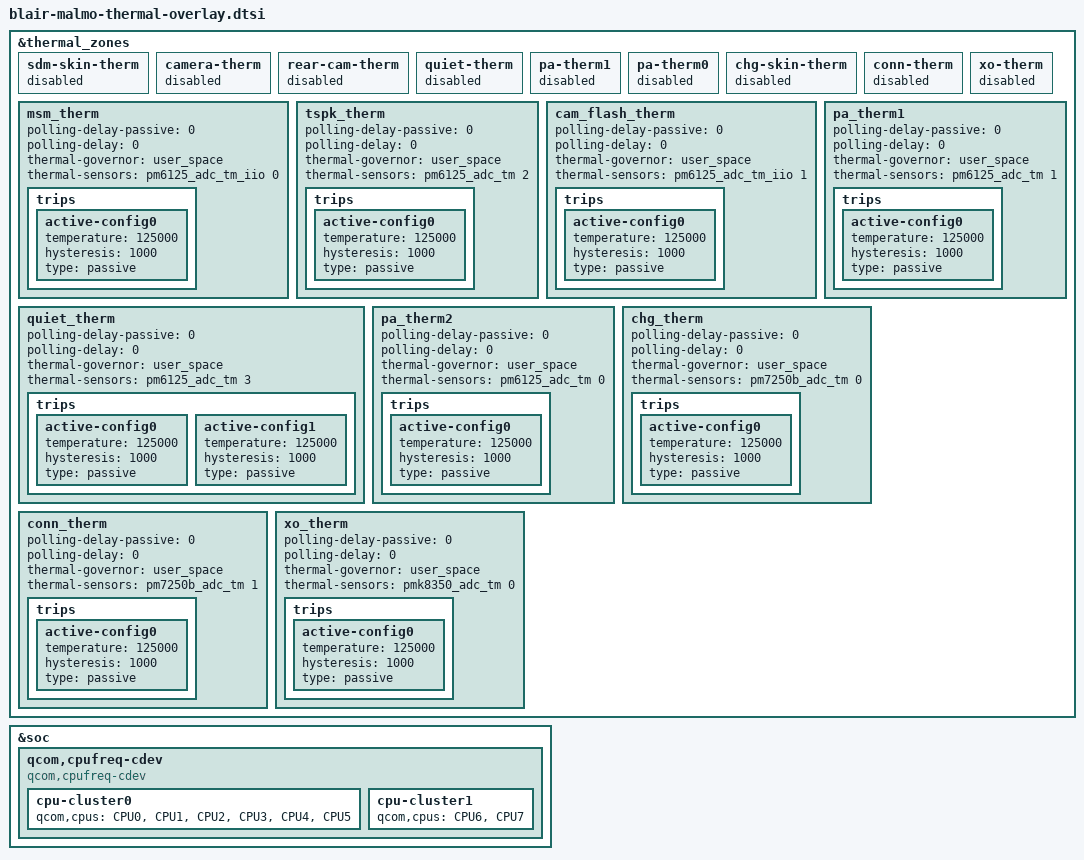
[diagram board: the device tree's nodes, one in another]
#include "moto_therm_sys_temp.dtsi"

/*
&socd_trip {
	temperature = <98>;
};
*/

&thermal_zones {
	sdm-skin-therm {
		status = "disabled";
	};

	camera-therm {
		status = "disabled";
	};

	rear-cam-therm {
		status = "disabled";
	};

	quiet-therm {
		status = "disabled";
	};

	pa-therm1 {
		status = "disabled";
	};

	pa-therm0 {
		status = "disabled";
	};

	chg-skin-therm {
		status = "disabled";
	};

	conn-therm {
		status = "disabled";
	};

	xo-therm {
		status = "disabled";
	};

	msm_therm {
		polling-delay-passive = <0>;
		polling-delay = <0>;
		thermal-governor = "user_space";
		thermal-sensors = <&pm6125_adc_tm_iio 0>;
		trips {
			active-config0 {
				temperature = <125000>;
				hysteresis = <1000>;
				type = "passive";
			};
		};
	};

	tspk_therm {
		polling-delay-passive = <0>;
		polling-delay = <0>;
		thermal-governor = "user_space";
		thermal-sensors = <&pm6125_adc_tm 2>;
		trips {
			active-config0 {
				temperature = <125000>;
				hysteresis = <1000>;
				type = "passive";
			};
		};
	};

	cam_flash_therm {
		polling-delay-passive = <0>;
		polling-delay = <0>;
		thermal-governor = "user_space";
		thermal-sensors = <&pm6125_adc_tm_iio 1>;
		trips {
			active-config0 {
				temperature = <125000>;
				hysteresis = <1000>;
				type = "passive";
			};
		};
	};

	quiet_therm {
		polling-delay-passive = <0>;
		polling-delay = <0>;
		thermal-governor = "user_space";
		thermal-sensors = <&pm6125_adc_tm 3>;
		trips {
			active-config0 {
				temperature = <125000>;
				hysteresis = <1000>;
				type = "passive";
			};

			active-config1 {
				temperature = <125000>;
				hysteresis = <1000>;
				type = "passive";
			};
		};
	};

	pa_therm1 {
		polling-delay-passive = <0>;
		polling-delay = <0>;
		thermal-governor = "user_space";
		thermal-sensors = <&pm6125_adc_tm 1>;
		trips {
			active-config0 {
				temperature = <125000>;
				hysteresis = <1000>;
				type = "passive";
			};
		};
	};

	pa_therm2 {
		polling-delay-passive = <0>;
		polling-delay = <0>;
		thermal-governor = "user_space";
		thermal-sensors = <&pm6125_adc_tm 0>;
		trips {
			active-config0 {
				temperature = <125000>;
				hysteresis = <1000>;
				type = "passive";
			};
		};
	};

	chg_therm {
		polling-delay-passive = <0>;
		polling-delay = <0>;
		thermal-governor = "user_space";
		thermal-sensors = <&pm7250b_adc_tm 0>;
			trips {
				active-config0 {
				temperature = <125000>;
				hysteresis = <1000>;
				type = "passive";
			};
		};
	};

	conn_therm {
		polling-delay-passive = <0>;
		polling-delay = <0>;
		thermal-governor = "user_space";
		thermal-sensors = <&pm7250b_adc_tm 1>;
		trips {
			active-config0 {
				temperature = <125000>;
				hysteresis = <1000>;
				type = "passive";
			};
		};
	};

	xo_therm {
		polling-delay-passive = <0>;
		polling-delay = <0>;
		thermal-governor = "user_space";
		thermal-sensors = <&pmk8350_adc_tm 0>;
		trips {
			active-config0 {
				temperature = <125000>;
				hysteresis = <1000>;
				type = "passive";
			};
		};
	};
};

&soc {
	qcom,cpufreq-cdev {
		compatible = "qcom,cpufreq-cdev";

		cpu-cluster0 {
			qcom,cpus = <&CPU0 &CPU1 &CPU2 &CPU3 &CPU4 &CPU5>;
		};

		cpu-cluster1 {
			qcom,cpus = <&CPU6 &CPU7>;
		};
	};
};
